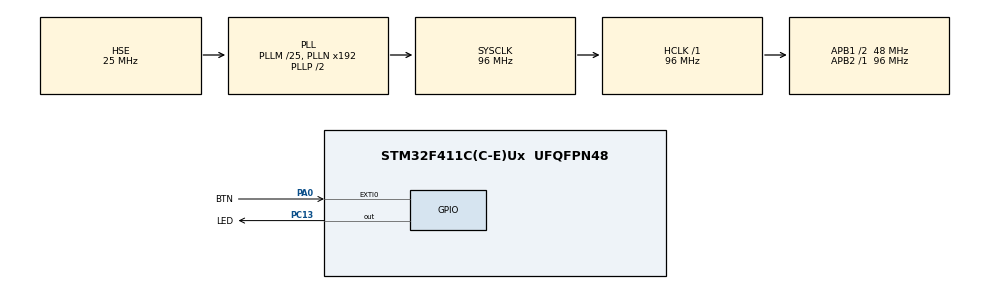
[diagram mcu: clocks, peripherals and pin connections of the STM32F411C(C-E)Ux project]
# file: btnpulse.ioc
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Mcu.Family=STM32F4
Mcu.Name=STM32F411C(C-E)Ux
Mcu.Package=UFQFPN48
Mcu.UserConstants=LED_CNT,9599;LED_PRE,9999
NVIC.EXTI0_IRQn=true\:0\:0\:false\:false\:true\:true\:true
NVIC.PriorityGroup=NVIC_PRIORITYGROUP_4
NVIC.TIM5_IRQn=true\:0\:0\:false\:false\:true\:true\:true
PA0-WKUP.GPIO_Label=BTN
PA0-WKUP.GPIO_ModeDefaultEXTI=GPIO_MODE_IT_FALLING
PA0-WKUP.GPIO_PuPd=GPIO_PULLUP
PA0-WKUP.Signal=GPXTI0
PA13.Mode=Serial_Wire
PA13.Signal=SYS_JTMS-SWDIO
PA14.Mode=Serial_Wire
PA14.Signal=SYS_JTCK-SWCLK
PC13-ANTI_TAMP.GPIO_Label=LED
PC13-ANTI_TAMP.GPIO_ModeDefaultOutputPP=GPIO_MODE_OUTPUT_OD
PC13-ANTI_TAMP.PinState=GPIO_PIN_SET
PC13-ANTI_TAMP.Signal=GPIO_Output
PH0\ -\ OSC_IN.Mode=HSE-External-Oscillator
PH0\ -\ OSC_IN.Signal=RCC_OSC_IN
PH1\ -\ OSC_OUT.Mode=HSE-External-Oscillator
PH1\ -\ OSC_OUT.Signal=RCC_OSC_OUT
ProjectManager.HeapSize=0x200
ProjectManager.StackSize=0x400
ProjectManager.TargetToolchain=STM32CubeIDE
RCC.48MHZClocksFreq_Value=48000000
RCC.AHBFreq_Value=96000000
RCC.APB1CLKDivider=RCC_HCLK_DIV2
RCC.APB1Freq_Value=48000000
RCC.APB1TimFreq_Value=96000000
RCC.APB2Freq_Value=96000000
RCC.APB2TimFreq_Value=96000000
RCC.CortexFreq_Value=96000000
RCC.HCLKFreq_Value=96000000
RCC.HSE_VALUE=25000000
RCC.HSI_VALUE=16000000
RCC.LSE_VALUE=32768
RCC.PLLM=25
RCC.PLLSourceVirtual=RCC_PLLSOURCE_HSE
RCC.SYSCLKFreq_VALUE=96000000
RCC.SYSCLKSource=RCC_SYSCLKSOURCE_PLLCLK
RCC.VCOOutputFreq_Value=192000000
TIM5.CounterMode=TIM_COUNTERMODE_DOWN
TIM5.Period=LED_CNT
TIM5.Prescaler=LED_PRE
TIM5.TIM_MasterOutputTrigger=TIM_TRGO_UPDATE
VP_TIM5_VS_ClockSourceINT.Mode=Internal
board=custom

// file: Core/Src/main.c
/* USER CODE BEGIN Header */
/**
 ******************************************************************************
 * @file           : main.c
 * @brief          : Main program body
 ******************************************************************************
 * @attention
 *
 * <h2><center>&copy; Copyright (c) 2021 lbthomsen@gmail.com.
 * All rights reserved.</center></h2>
 *
 * This software component is licensed by ST under MITe license,
 * the "License"; You may not use this file except in compliance with the
 * License. You may obtain a copy of the License at:
 *                        opensource.org/licenses/MIT
 *
 ******************************************************************************
 */
/* USER CODE END Header */
#include "main.h"

/* USER CODE BEGIN PD */

#define LED_PRE 9599 // Timer clock at 96 MHz - so 1 count = 0.1ms
#define LED_CNT 4999 // 0.5 sec

/* USER CODE END PD */

TIM_HandleTypeDef htim5;

void SystemClock_Config(void);
static void MX_GPIO_Init(void);
static void MX_TIM5_Init(void);

/* USER CODE BEGIN 0 */

void HAL_TIM_PeriodElapsedCallback(TIM_HandleTypeDef *htim) {
	if (htim->Instance == TIM5) {
		HAL_GPIO_WritePin(LED_GPIO_Port, LED_Pin, GPIO_PIN_SET); // Off LED
		HAL_TIM_Base_Stop(&htim5); // Kill the Timer
	}
}

void HAL_GPIO_EXTI_Callback(uint16_t GPIO_Pin) {
	if (GPIO_Pin == BTN_Pin) // If the button
	{

		HAL_GPIO_WritePin(LED_GPIO_Port, LED_Pin, GPIO_PIN_RESET); // Switch LED ON

		if (__HAL_TIM_GET_COUNTER(&htim5) == LED_CNT) { // Check if Timer is running - sort of
			HAL_TIM_Base_Start_IT(&htim5); // Start the timer if not running
		} else {
			__HAL_TIM_SET_COUNTER(&htim5, LED_CNT); // Reset the timer IF running
		}
	}
}

/* USER CODE END 0 */

int main(void)
{

  /* MCU Configuration--------------------------------------------------------*/

  /* Reset of all peripherals, Initializes the Flash interface and the Systick. */
  HAL_Init();

  /* Configure the system clock */
  SystemClock_Config();

  /* Initialize all configured peripherals */
  MX_GPIO_Init();
  MX_TIM5_Init();

  /* Infinite loop */
	while (1) {

	}
}

void SystemClock_Config(void)
{
  RCC_OscInitTypeDef RCC_OscInitStruct = {0};
  RCC_ClkInitTypeDef RCC_ClkInitStruct = {0};

  /** Configure the main internal regulator output voltage
  */
  __HAL_RCC_PWR_CLK_ENABLE();
  __HAL_PWR_VOLTAGESCALING_CONFIG(PWR_REGULATOR_VOLTAGE_SCALE1);
  /** Initializes the RCC Oscillators according to the specified parameters
  * in the RCC_OscInitTypeDef structure.
  */
  RCC_OscInitStruct.OscillatorType = RCC_OSCILLATORTYPE_HSE;
  RCC_OscInitStruct.HSEState = RCC_HSE_ON;
  RCC_OscInitStruct.PLL.PLLState = RCC_PLL_ON;
  RCC_OscInitStruct.PLL.PLLSource = RCC_PLLSOURCE_HSE;
  RCC_OscInitStruct.PLL.PLLM = 25;
  RCC_OscInitStruct.PLL.PLLN = 192;
  RCC_OscInitStruct.PLL.PLLP = RCC_PLLP_DIV2;
  RCC_OscInitStruct.PLL.PLLQ = 4;
  if (HAL_RCC_OscConfig(&RCC_OscInitStruct) != HAL_OK)
  {
    Error_Handler();
  }
  /** Initializes the CPU, AHB and APB buses clocks
  */
  RCC_ClkInitStruct.ClockType = RCC_CLOCKTYPE_HCLK|RCC_CLOCKTYPE_SYSCLK
                              |RCC_CLOCKTYPE_PCLK1|RCC_CLOCKTYPE_PCLK2;
  RCC_ClkInitStruct.SYSCLKSource = RCC_SYSCLKSOURCE_PLLCLK;
  RCC_ClkInitStruct.AHBCLKDivider = RCC_SYSCLK_DIV1;
  RCC_ClkInitStruct.APB1CLKDivider = RCC_HCLK_DIV2;
  RCC_ClkInitStruct.APB2CLKDivider = RCC_HCLK_DIV1;

  if (HAL_RCC_ClockConfig(&RCC_ClkInitStruct, FLASH_LATENCY_3) != HAL_OK)
  {
    Error_Handler();
  }
}

static void MX_TIM5_Init(void)
{

  TIM_ClockConfigTypeDef sClockSourceConfig = {0};
  TIM_MasterConfigTypeDef sMasterConfig = {0};

  htim5.Instance = TIM5;
  htim5.Init.Prescaler = LED_PRE;
  htim5.Init.CounterMode = TIM_COUNTERMODE_DOWN;
  htim5.Init.Period = LED_CNT;
  htim5.Init.ClockDivision = TIM_CLOCKDIVISION_DIV1;
  htim5.Init.AutoReloadPreload = TIM_AUTORELOAD_PRELOAD_DISABLE;
  if (HAL_TIM_Base_Init(&htim5) != HAL_OK)
  {
    Error_Handler();
  }
  sClockSourceConfig.ClockSource = TIM_CLOCKSOURCE_INTERNAL;
  if (HAL_TIM_ConfigClockSource(&htim5, &sClockSourceConfig) != HAL_OK)
  {
    Error_Handler();
  }
  sMasterConfig.MasterOutputTrigger = TIM_TRGO_UPDATE;
  sMasterConfig.MasterSlaveMode = TIM_MASTERSLAVEMODE_DISABLE;
  if (HAL_TIMEx_MasterConfigSynchronization(&htim5, &sMasterConfig) != HAL_OK)
  {
    Error_Handler();
  }

}

static void MX_GPIO_Init(void)
{
  GPIO_InitTypeDef GPIO_InitStruct = {0};

  /* GPIO Ports Clock Enable */
  __HAL_RCC_GPIOC_CLK_ENABLE();
  __HAL_RCC_GPIOH_CLK_ENABLE();
  __HAL_RCC_GPIOA_CLK_ENABLE();

  /*Configure GPIO pin Output Level */
  HAL_GPIO_WritePin(LED_GPIO_Port, LED_Pin, GPIO_PIN_SET);

  /*Configure GPIO pin : LED_Pin */
  GPIO_InitStruct.Pin = LED_Pin;
  GPIO_InitStruct.Mode = GPIO_MODE_OUTPUT_OD;
  GPIO_InitStruct.Pull = GPIO_NOPULL;
  GPIO_InitStruct.Speed = GPIO_SPEED_FREQ_LOW;
  HAL_GPIO_Init(LED_GPIO_Port, &GPIO_InitStruct);

  /*Configure GPIO pin : BTN_Pin */
  GPIO_InitStruct.Pin = BTN_Pin;
  GPIO_InitStruct.Mode = GPIO_MODE_IT_FALLING;
  GPIO_InitStruct.Pull = GPIO_PULLUP;
  HAL_GPIO_Init(BTN_GPIO_Port, &GPIO_InitStruct);

  /* EXTI interrupt init*/
  HAL_NVIC_SetPriority(EXTI0_IRQn, 0, 0);
  HAL_NVIC_EnableIRQ(EXTI0_IRQn);

}

void Error_Handler(void)
{
	__disable_irq();
	while (1) {
	}
}
